# PIC32MX340F512H register map
Vendor: Microchip
Registers are 32-bit, read-write, reset 0x0 unless marked. A register's access mark holds for its fields unless they carry their own. Addresses are absolute, and some are shared; only a register's first bit layout is shown; [hi:lo] are bit positions; {n}, {i} and the like mark numbered series.

## DMAC3
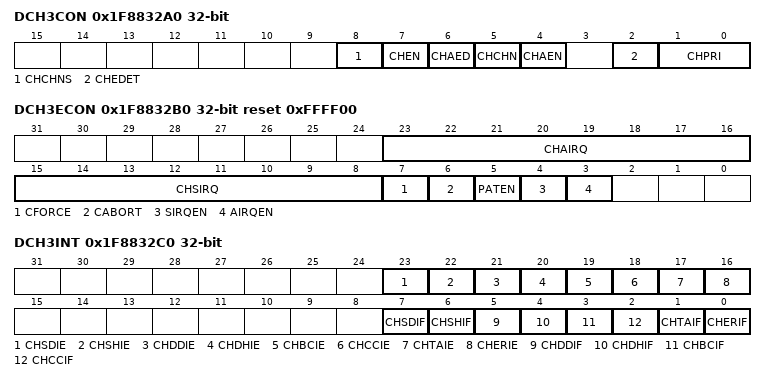
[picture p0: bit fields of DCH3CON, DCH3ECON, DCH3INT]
0x1F8832A0 DCH3CON
  [8] CHCHNS, [7] CHEN, [6] CHAED, [5] CHCHN, [4] CHAEN, [2] CHEDET ro, [1:0] CHPRI
0x1F8832B0 DCH3ECON reset 0xFFFF00
  [23:16] CHAIRQ
  [15:8] CHSIRQ
  [7] CFORCE — (can only be set)
  [6] CABORT — (can only be set)
  [5] PATEN
  [4] SIRQEN
  [3] AIRQEN
0x1F8832C0 DCH3INT
  [23] CHSDIE, [22] CHSHIE, [21] CHDDIE, [20] CHDHIE, [19] CHBCIE, [18] CHCCIE, [17] CHTAIE, [16] CHERIE, [7] CHSDIF, [6] CHSHIF, [5] CHDDIF, [4] CHDHIF, [3] CHBCIF, [2] CHCCIF, [1] CHTAIF, [0] CHERIF
0x1F8832D0 DCH3SSA reset not defined — (power-on value xxxxxxxxxxxxxxxxxxxxxxxxxxxxxxxx)
0x1F8832E0 DCH3DSA reset not defined — (power-on value xxxxxxxxxxxxxxxxxxxxxxxxxxxxxxxx)
0x1F8832F0 DCH3SSIZ reset not defined — (power-on value ----------------xxxxxxxxxxxxxxxx)
  [15:0] CHSSIZ
0x1F883300 DCH3DSIZ reset not defined — (power-on value ----------------xxxxxxxxxxxxxxxx)
  [15:0] CHDSIZ
0x1F883310 DCH3SPTR reset not defined — (power-on value ----------------xxxxxxxxxxxxxxxx)
  [15:0] CHSPTR
0x1F883320 DCH3DPTR ro
  [15:0] CHDPTR
0x1F883330 DCH3CSIZ reset not defined — (power-on value ----------------xxxxxxxxxxxxxxxx)
  [15:0] CHCSIZ
0x1F883340 DCH3CPTR reset not defined — (power-on value ----------------xxxxxxxxxxxxxxxx)
  [15:0] CHCPTR
0x1F883350 DCH3DAT reset not defined — (power-on value ------------------------xxxxxxxx)
  [7:0] DCHPDAT

## PCACHE
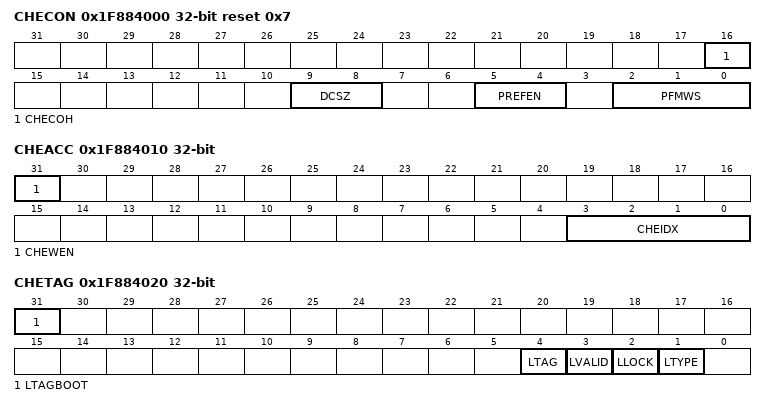
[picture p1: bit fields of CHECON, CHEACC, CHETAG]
0x1F884000 CHECON reset 0x7
  [16] CHECOH, [9:8] DCSZ, [5:4] PREFEN, [2:0] PFMWS
0x1F884010 CHEACC
  [31] CHEWEN, [3:0] CHEIDX
0x1F884020 CHETAG reset not defined — (power-on value 0xxxxxxxxxxxxxxxxxxxxxxxxxxx0010)
  [31] LTAGBOOT, [4] LTAG, [3] LVALID, [2] LLOCK, [1] LTYPE
0x1F884030 CHEMSK
  [15:5] LMASK
{0x1F884040+0x10*i} CHEW{i} reset not defined (i=0..3) — (power-on value xxxxxxxxxxxxxxxxxxxxxxxxxxxxxxxx)
0x1F884080 CHELRU
  [24:0] CHELRU
0x1F884090 CHEHIT reset not defined — (power-on value xxxxxxxxxxxxxxxxxxxxxxxxxxxxxxxx)
  [31:0] CHEHIT — (can only be cleared)
0x1F8840A0 CHEMIS reset not defined — (power-on value xxxxxxxxxxxxxxxxxxxxxxxxxxxxxxxx)
  [31:0] CHEMIS — (can only be cleared)
0x1F8840C0 CHEPFABT reset not defined — (power-on value xxxxxxxxxxxxxxxxxxxxxxxxxxxxxxxx)
  [31:0] CHEPFABT — (can only be cleared)

## YPAA_Ports
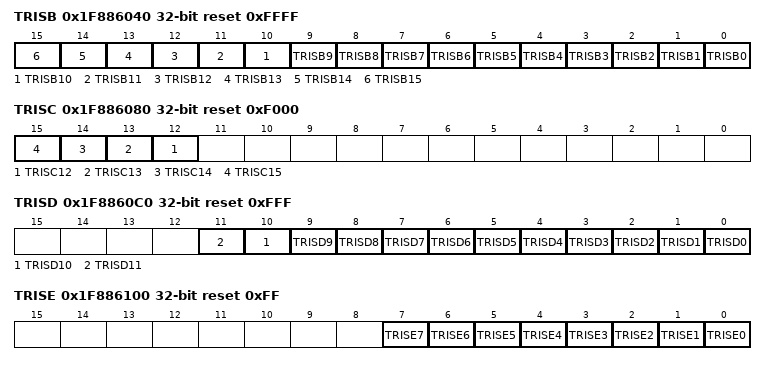
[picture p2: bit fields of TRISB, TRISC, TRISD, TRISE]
0x1F886040 TRISB reset 0xFFFF
  [n] TRISB{n} (n=0..15)
0x1F886080 TRISC reset 0xF000
  [n] TRISC{n} (n=12..15)
0x1F8860C0 TRISD reset 0xFFF
  [n] TRISD{n} (n=0..11)
0x1F886100 TRISE reset 0xFF
  [n] TRISE{n} (n=0..7)
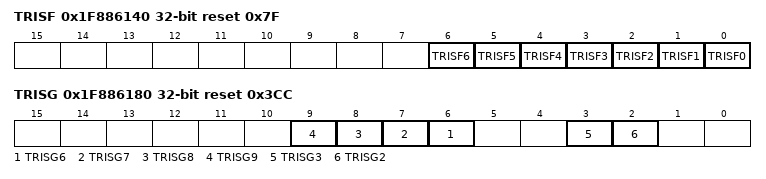
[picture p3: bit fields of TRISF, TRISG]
0x1F886140 TRISF reset 0x7F
  [n] TRISF{n} (n=0..6)
0x1F886180 TRISG reset 0x3CC
  [n] TRISG{n} (n=6..9), [3] TRISG3, [2] TRISG2

## PORTB
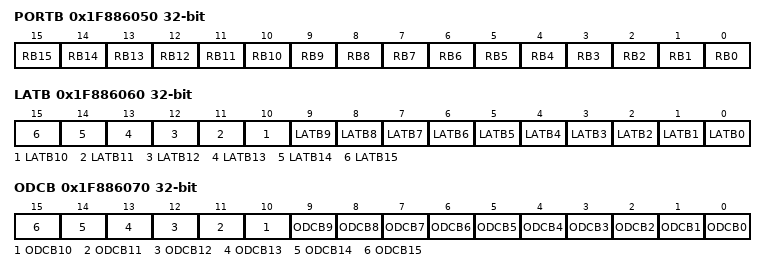
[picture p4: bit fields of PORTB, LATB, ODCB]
0x1F886050 PORTB reset not defined — (power-on value ----------------xxxxxxxxxxxxxxxx)
  [n] RB{n} (n=0..15)
0x1F886060 LATB reset not defined — (power-on value ----------------xxxxxxxxxxxxxxxx)
  [n] LATB{n} (n=0..15)
0x1F886070 ODCB
  [n] ODCB{n} (n=0..15)

## PORTC
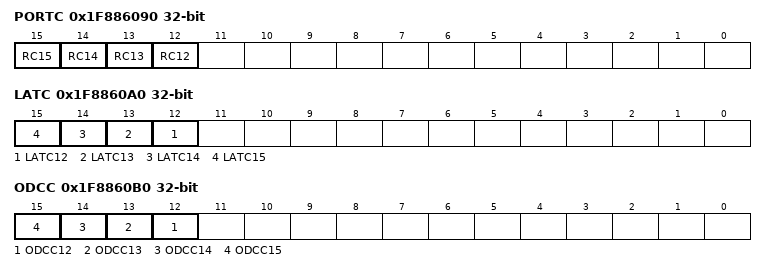
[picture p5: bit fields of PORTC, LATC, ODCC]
0x1F886090 PORTC reset not defined — (power-on value ----------------xxxx------------)
  [n] RC{n} (n=12..15)
0x1F8860A0 LATC reset not defined — (power-on value ----------------xxxx------------)
  [n] LATC{n} (n=12..15)
0x1F8860B0 ODCC
  [n] ODCC{n} (n=12..15)

## PORTD
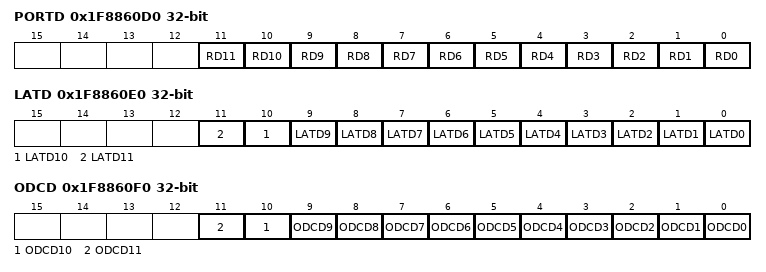
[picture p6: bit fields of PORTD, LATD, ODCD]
0x1F8860D0 PORTD reset not defined — (power-on value --------------------xxxxxxxxxxxx)
  [n] RD{n} (n=0..11)
0x1F8860E0 LATD reset not defined — (power-on value --------------------xxxxxxxxxxxx)
  [n] LATD{n} (n=0..11)
0x1F8860F0 ODCD
  [n] ODCD{n} (n=0..11)

## PORTE
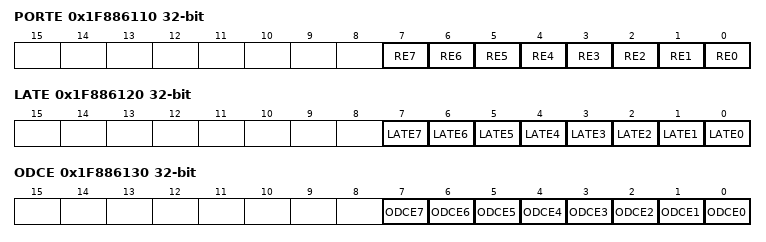
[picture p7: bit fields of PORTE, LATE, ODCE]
0x1F886110 PORTE reset not defined — (power-on value ------------------------xxxxxxxx)
  [n] RE{n} (n=0..7)
0x1F886120 LATE reset not defined — (power-on value ------------------------xxxxxxxx)
  [n] LATE{n} (n=0..7)
0x1F886130 ODCE
  [n] ODCE{n} (n=0..7)

## PORTF
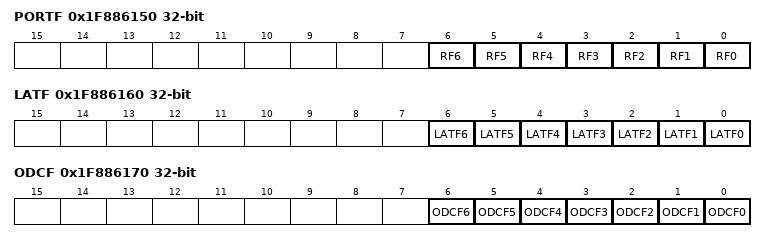
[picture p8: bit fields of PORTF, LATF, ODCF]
0x1F886150 PORTF reset not defined — (power-on value -------------------------xxxxxxx)
  [n] RF{n} (n=0..6)
0x1F886160 LATF reset not defined — (power-on value -------------------------xxxxxxx)
  [n] LATF{n} (n=0..6)
0x1F886170 ODCF
  [n] ODCF{n} (n=0..6)

## PORTG
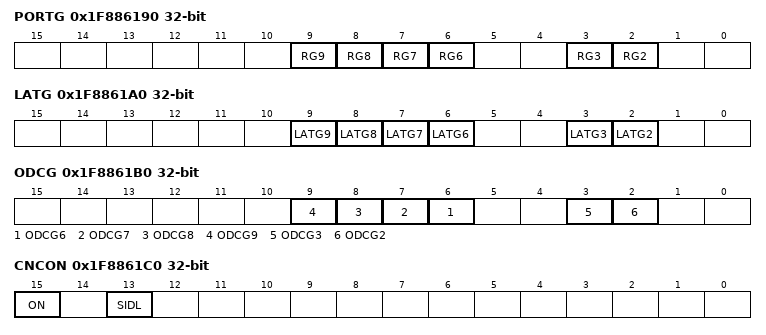
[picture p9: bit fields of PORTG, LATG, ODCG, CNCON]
0x1F886190 PORTG reset not defined — (power-on value ----------------------xxxx--xx--)
  [n] RG{n} (n=6..9), [3] RG3, [2] RG2
0x1F8861A0 LATG reset not defined — (power-on value ----------------------xxxx--xx--)
  [n] LATG{n} (n=6..9), [3] LATG3, [2] LATG2
0x1F8861B0 ODCG
  [n] ODCG{n} (n=6..9), [3] ODCG3, [2] ODCG2
0x1F8861C0 CNCON
  [15] ON, [13] SIDL
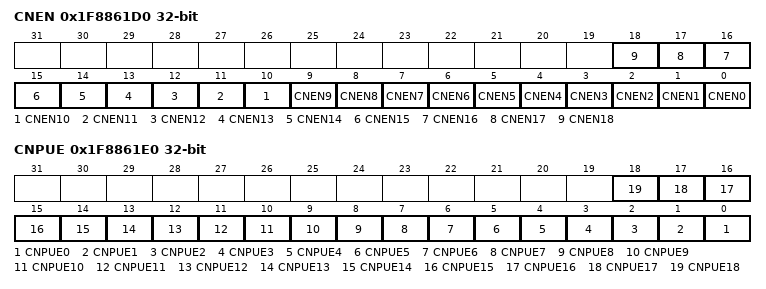
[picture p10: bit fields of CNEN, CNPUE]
0x1F8861D0 CNEN
  [n] CNEN{n} (n=0..18)
0x1F8861E0 CNPUE
  [n] CNPUE{n} (n=0..18)
